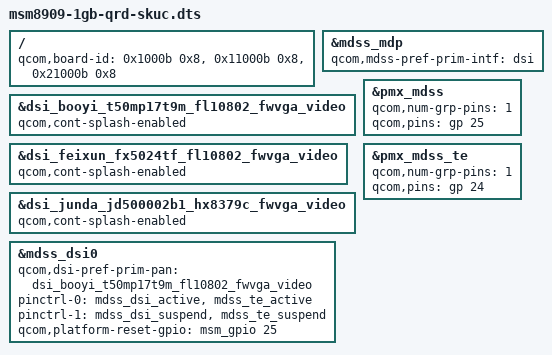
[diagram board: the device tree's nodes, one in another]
/* Copyright (c) 2014, The Linux Foundation. All rights reserved.
 *
 * This program is free software; you can redistribute it and/or modify
 * it under the terms of the GNU General Public License version 2 and
 * only version 2 as published by the Free Software Foundation.
 *
 * This program is distributed in the hope that it will be useful,
 * but WITHOUT ANY WARRANTY; without even the implied warranty of
 * MERCHANTABILITY or FITNESS FOR A PARTICULAR PURPOSE.  See the
 * GNU General Public License for more details.
 */

/dts-v1/;

#include "msm8909-qrd-skuc.dtsi"
#include "c630lw-dsi-panel-booyi-t50mp17t9m_fl10802_50_fwvga-video.dtsi"
#include "c630lw-dsi-panel-feixun-fx5024tf-fl10802-50-fwvga-video.dtsi"
#include "c630lw-dsi-panel-junda-jd500002b1-hx8379c-50-fwvga-video.dtsi"


/ {
	qcom,board-id= <0x1000b 0x8>, <0x11000b 0x8>, <0x21000b 0x8>;
};

&mdss_mdp {
	qcom,mdss-pref-prim-intf = "dsi";
};

&dsi_booyi_t50mp17t9m_fl10802_fwvga_video {
	qcom,cont-splash-enabled;
};

&dsi_feixun_fx5024tf_fl10802_fwvga_video {
	qcom,cont-splash-enabled;
};

&dsi_junda_jd500002b1_hx8379c_fwvga_video {
	qcom,cont-splash-enabled;
};

&pmx_mdss {
	qcom,num-grp-pins = <1>;
	qcom,pins = <&gp 25>;
};

&pmx_mdss_te {
	qcom,num-grp-pins = <1>;
	qcom,pins = <&gp 24>;
};

&mdss_dsi0 {
	qcom,dsi-pref-prim-pan = <&dsi_booyi_t50mp17t9m_fl10802_fwvga_video>;
	pinctrl-names = "mdss_default", "mdss_sleep";
	pinctrl-0 = <&mdss_dsi_active &mdss_te_active>;
	pinctrl-1 = <&mdss_dsi_suspend &mdss_te_suspend>;

	qcom,platform-reset-gpio = <&msm_gpio 25 0>;
};
